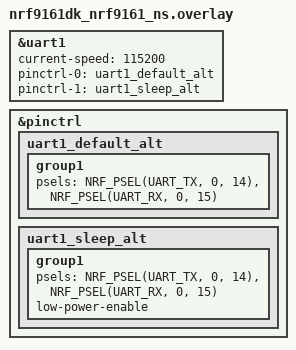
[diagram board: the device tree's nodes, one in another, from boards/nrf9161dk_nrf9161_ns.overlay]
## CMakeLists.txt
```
cmake_minimum_required(VERSION 3.20.0)

# Tell Zephyr where to find our custom YAML blueprints BEFORE finding Zephyr
list(APPEND DTS_ROOT ${CMAKE_CURRENT_SOURCE_DIR})

find_package(Zephyr REQUIRED HINTS $ENV{ZEPHYR_BASE})
project(EmbeddedSystem LANGUAGES C CXX)

zephyr_include_directories(include)

# Add both your main app AND your new kernel driver to the build
target_sources(app PRIVATE 
    src/main.cpp
    src/graphics.cpp
    src/shell.cpp
    src/state.cpp
    src/footprint.cpp
    src/virtual_sensor.c
)
```

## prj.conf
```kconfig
# Enable the hardware console peripheral and logging pipelines
CONFIG_GPIO=y
CONFIG_SERIAL=y
CONFIG_CONSOLE=y

# Enable internal GDB debugging hooks
CONFIG_DEBUG=y

# Disable heavy compiler optimization so code maps 1:1 with source files
CONFIG_DEBUG_OPTIMIZATIONS=y

# Enable the Display subsystem
CONFIG_DISPLAY=y

# Enable the SDL (Window) Display Driver
CONFIG_SDL_DISPLAY=y

# Enable standard C++ library support (provides the 'new' and 'delete' operators)
CONFIG_CPP=y

# Give the RTOS a standard system heap size
CONFIG_HEAP_MEM_POOL_SIZE=16384

# Set custom Boot Banner to 'Vidya OS'
CONFIG_BOOT_BANNER=y
CONFIG_BOOT_BANNER_STRING="Booting Vidya OS"

# Enable reboot APIs
CONFIG_REBOOT=y

# Enable full C++ standard library support (using host compiler's STL on native_sim)
CONFIG_REQUIRES_FULL_LIBCPP=y
CONFIG_STD_CPP17=y

# Enable standard Zephyr Sensor Subsystem
CONFIG_SENSOR=y

# Enable Zephyr's portable console subsystem and getline utilities
CONFIG_CONSOLE_SUBSYS=y
CONFIG_CONSOLE_GETLINE=y
```

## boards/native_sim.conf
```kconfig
# native_sim specific configurations
CONFIG_HEAP_MEM_POOL_SIZE=1048576
```

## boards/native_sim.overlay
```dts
/* boards/native_sim.overlay */

/ {
    my_custom_sensor: virtual_sensor_0 {
        compatible = "custom,virtual-sensor";
        status = "okay";
    };
};

&sdl_dc {
    status = "okay";
};
```

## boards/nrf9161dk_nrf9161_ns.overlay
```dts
&uart1 {
    status = "okay";
    current-speed = <115200>;
    pinctrl-0 = <&uart1_default_alt>;
    pinctrl-1 = <&uart1_sleep_alt>;
    pinctrl-names = "default", "sleep";
};

&pinctrl {
    uart1_default_alt: uart1_default_alt {
        group1 {
            psels = <NRF_PSEL(UART_TX, 0, 14)>,
                    <NRF_PSEL(UART_RX, 0, 15)>;
        };
    };

    uart1_sleep_alt: uart1_sleep_alt {
        group1 {
            psels = <NRF_PSEL(UART_TX, 0, 14)>,
                    <NRF_PSEL(UART_RX, 0, 15)>;
            low-power-enable;
        };
    };
};
```

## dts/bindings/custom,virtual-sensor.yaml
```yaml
# dts/bindings/custom,virtual-sensor.yaml
description: A custom virtual sensor for the OS simulator
compatible: "custom,virtual-sensor"
include: sensor-device.yaml
```

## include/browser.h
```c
#pragma once
// ─────────────────────────────────────────────────────────────────────────────
//  browser.h — Real internet browser backend for VidyaOS
//  Uses libcurl to fetch real HTTP/HTTPS pages and strips HTML to text.
// ─────────────────────────────────────────────────────────────────────────────
#include <string>
#include <vector>
#include <functional>

// ── Page link extracted from HTML ────────────────────────────────────────────
struct ParsedLink {
    std::string href;
    std::string text;
};

// ── Result of a fetch ────────────────────────────────────────────────────────
struct FetchResult {
    bool        success;
    int         http_code;       // 200, 404, etc.
    std::string final_url;       // After redirects
    std::string content_type;
    std::string raw_body;        // Full HTML
    std::string plain_text;      // Stripped text for display
    std::vector<std::string>     lines;  // pre-wrapped display lines
    std::vector<ParsedLink>      links;  // extracted <a href> links
    std::string error_message;
};

// ── Public API ───────────────────────────────────────────────────────────────

// Asynchronous fetch — triggers a background thread.
// Call is_fetching() to poll completion, then get_fetch_result().
void browser_fetch_async(const std::string& url);

// Returns true while a fetch is in progress.
bool browser_is_fetching();

// Returns the last completed fetch result. Safe to call from render thread.
const FetchResult& browser_get_result();

// Returns a normalised URL from user input (adds https:// etc.)
std::string browser_normalise_url(const std::string& input);

// Strip HTML tags and decode entities, return plain text lines.
std::vector<std::string> html_to_lines(const std::string& html, int wrap_chars, std::vector<ParsedLink>& links_out);
```

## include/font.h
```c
#ifndef FONT_H
#define FONT_H

#include <stdint.h>

static const uint8_t font8x8[96][8] = {
    {0x00, 0x00, 0x00, 0x00, 0x00, 0x00, 0x00, 0x00}, // (space)
    {0x18, 0x3C, 0x3C, 0x18, 0x18, 0x00, 0x18, 0x00}, // !
    {0x6C, 0x6C, 0x00, 0x00, 0x00, 0x00, 0x00, 0x00}, // "
    {0x36, 0x36, 0x7F, 0x36, 0x7F, 0x36, 0x36, 0x00}, // #
    {0x0C, 0x3E, 0x03, 0x1E, 0x30, 0x1F, 0x0C, 0x00}, // $
    {0x00, 0x66, 0x30, 0x18, 0x0C, 0x66, 0x00, 0x00}, // %
    {0x3C, 0x66, 0x3C, 0x38, 0x67, 0x66, 0x3F, 0x00}, // &
    {0x06, 0x0C, 0x18, 0x00, 0x00, 0x00, 0x00, 0x00}, // '
    {0x0C, 0x18, 0x30, 0x30, 0x30, 0x18, 0x0C, 0x00}, // (
    {0x30, 0x18, 0x0C, 0x0C, 0x0C, 0x18, 0x30, 0x00}, // )
    {0x00, 0x66, 0x3C, 0xFF, 0x3C, 0x66, 0x00, 0x00}, // *
    {0x00, 0x18, 0x18, 0x7E, 0x18, 0x18, 0x00, 0x00}, // +
    {0x00, 0x00, 0x00, 0x00, 0x00, 0x18, 0x18, 0x30}, // ,
    {0x00, 0x00, 0x00, 0x7E, 0x00, 0x00, 0x00, 0x00}, // -
    {0x00, 0x00, 0x00, 0x00, 0x00, 0x18, 0x18, 0x00}, // .
    {0x00, 0x03, 0x06, 0x0C, 0x18, 0x30, 0x60, 0x00}, // /
    {0x3E, 0x63, 0x67, 0x6F, 0x7B, 0x63, 0x3E, 0x00}, // 0
    {0x0C, 0x0E, 0x0C, 0x0C, 0x0C, 0x0C, 0x3F, 0x00}, // 1
    {0x1E, 0x33, 0x30, 0x1C, 0x06, 0x33, 0x3F, 0x00}, // 2
    {0x1E, 0x33, 0x30, 0x1C, 0x30, 0x33, 0x1E, 0x00}, // 3
    {0x38, 0x3C, 0x36, 0x33, 0x7F, 0x30, 0x78, 0x00}, // 4
    {0x3F, 0x03, 0x1F, 0x30, 0x30, 0x33, 0x1E, 0x00}, // 5
    {0x1C, 0x06, 0x03, 0x1F, 0x33, 0x33, 0x1E, 0x00}, // 6
    {0x3F, 0x33, 0x30, 0x18, 0x0C, 0x0C, 0x0C, 0x00}, // 7
    {0x1E, 0x33, 0x33, 0x1E, 0x33, 0x33, 0x1E, 0x00}, // 8
    {0x1E, 0x33, 0x33, 0x3E, 0x30, 0x18, 0x0E, 0x00}, // 9
    {0x00, 0x18, 0x18, 0x00, 0x18, 0x18, 0x00, 0x00}, // :
    {0x00, 0x18, 0x18, 0x00, 0x18, 0x18, 0x30, 0x00}, // ;
    {0x00, 0x0C, 0x18, 0x30, 0x18, 0x0C, 0x00, 0x00}, // <
    {0x00, 0x00, 0x7E, 0x00, 0x7E, 0x00, 0x00, 0x00}, // =
    {0x00, 0x30, 0x18, 0x0C, 0x18, 0x30, 0x00, 0x00}, // >
    {0x1E, 0x33, 0x30, 0x18, 0x0C, 0x00, 0x0C, 0x00}, // ?
    {0x3E, 0x63, 0x7B, 0x7B, 0x7B, 0x03, 0x1E, 0x00}, // @
    {0x0C, 0x1E, 0x33, 0x33, 0x3F, 0x33, 0x33, 0x00}, // A
    {0x3F, 0x66, 0x66, 0x3F, 0x66, 0x66, 0x3F, 0x00}, // B
    {0x3C, 0x66, 0x03, 0x03, 0x03, 0x66, 0x3C, 0x00}, // C
    {0x1F, 0x36, 0x66, 0x66, 0x66, 0x36, 0x1F, 0x00}, // D
    {0x3F, 0x06, 0x06, 0x1E, 0x06, 0x06, 0x3F, 0x00}, // E
    {0x3F, 0x06, 0x06, 0x1E, 0x06, 0x06, 0x06, 0x00}, // F
    {0x3C, 0x66, 0x03, 0x3B, 0x66, 0x66, 0x3C, 0x00}, // G
    {0x33, 0x33, 0x33, 0x3F, 0x33, 0x33, 0x33, 0x00}, // H
    {0x1E, 0x0C, 0x0C, 0x0C, 0x0C, 0x0C, 0x1E, 0x00}, // I
    {0x78, 0x30, 0x30, 0x30, 0x33, 0x33, 0x1E, 0x00}, // J
    {0x33, 0x36, 0x3C, 0x3C, 0x36, 0x33, 0x33, 0x00}, // K
    {0x06, 0x06, 0x06, 0x06, 0x06, 0x06, 0x3F, 0x00}, // L
    {0x63, 0x77, 0x7F, 0x6B, 0x63, 0x63, 0x63, 0x00}, // M
    {0x33, 0x3B, 0x3F, 0x37, 0x33, 0x33, 0x33, 0x00}, // N
    {0x1E, 0x33, 0x33, 0x33, 0x33, 0x33, 0x1E, 0x00}, // O
    {0x3F, 0x66, 0x66, 0x3F, 0x06, 0x06, 0x06, 0x00}, // P
    {0x1E, 0x33, 0x33, 0x33, 0x3B, 0x3B, 0x1E, 0x38}, // Q
    {0x3F, 0x66, 0x66, 0x3F, 0x36, 0x66, 0x63, 0x00}, // R
    {0x1E, 0x33, 0x07, 0x0E, 0x38, 0x33, 0x1E, 0x00}, // S
    {0x3F, 0x0C, 0x0C, 0x0C, 0x0C, 0x0C, 0x0C, 0x00}, // T
    {0x33, 0x33, 0x33, 0x33, 0x33, 0x33, 0x1E, 0x00}, // U
    {0x33, 0x33, 0x33, 0x33, 0x33, 0x1E, 0x0C, 0x00}, // V
    {0x63, 0x63, 0x63, 0x6B, 0x7F, 0x77, 0x63, 0x00}, // W
    {0x63, 0x63, 0x36, 0x1C, 0x36, 0x63, 0x63, 0x00}, // X
    {0x33, 0x33, 0x33, 0x1E, 0x0C, 0x0C, 0x0C, 0x00}, // Y
    {0x3F, 0x30, 0x18, 0x0C, 0x06, 0x03, 0x3F, 0x00}, // Z
    {0x3C, 0x0C, 0x0C, 0x0C, 0x0C, 0x0C, 0x3C, 0x00}, // [
    {0x00, 0x60, 0x30, 0x18, 0x0C, 0x06, 0x03, 0x00}, // backslash
    {0x3C, 0x30, 0x30, 0x30, 0x30, 0x30, 0x3C, 0x00}, // ]
    {0x08, 0x1C, 0x36, 0x63, 0x00, 0x00, 0x00, 0x00}, // ^
    {0x00, 0x00, 0x00, 0x00, 0x00, 0x00, 0x00, 0xFF}, // _
    {0x0C, 0x06, 0x03, 0x00, 0x00, 0x00, 0x00, 0x00}, // `
    {0x00, 0x00, 0x3E, 0x30, 0x3E, 0x33, 0x3E, 0x00}, // a
    {0x06, 0x06, 0x3E, 0x33, 0x33, 0x33, 0x3E, 0x00}, // b
    {0x00, 0x00, 0x3E, 0x03, 0x03, 0x03, 0x3E, 0x00}, // c
    {0x30, 0x30, 0x3E, 0x33, 0x33, 0x33, 0x3E, 0x00}, // d
    {0x00, 0x00, 0x3E, 0x33, 0x3F, 0x03, 0x3E, 0x00}, // e
    {0x1C, 0x36, 0x06, 0x1F, 0x06, 0x06, 0x06, 0x00}, // f
    {0x00, 0x00, 0x3E, 0x33, 0x33, 0x3E, 0x30, 0x1F}, // g
    {0x06, 0x06, 0x3E, 0x33, 0x33, 0x33, 0x33, 0x00}, // h
    {0x0C, 0x00, 0x0E, 0x0C, 0x0C, 0x0C, 0x1E, 0x00}, // i
    {0x30, 0x00, 0x30, 0x30, 0x30, 0x33, 0x33, 0x1E}, // j
    {0x06, 0x06, 0x33, 0x36, 0x3C, 0x36, 0x33, 0x00}, // k
    {0x0E, 0x0C, 0x0C, 0x0C, 0x0C, 0x0C, 0x1E, 0x00}, // l
    {0x00, 0x00, 0x66, 0x7F, 0x6B, 0x63, 0x63, 0x00}, // m
    {0x00, 0x00, 0x3E, 0x33, 0x33, 0x33, 0x33, 0x00}, // n
    {0x00, 0x00, 0x1E, 0x33, 0x33, 0x33, 0x1E, 0x00}, // o
    {0x00, 0x00, 0x3E, 0x33, 0x33, 0x3E, 0x06, 0x06}, // p
    {0x00, 0x00, 0x3E, 0x33, 0x33, 0x3E, 0x30, 0x30}, // q
    {0x00, 0x00, 0x3E, 0x33, 0x07, 0x06, 0x06, 0x00}, // r
    {0x00, 0x00, 0x1E, 0x03, 0x1E, 0x30, 0x1F, 0x00}, // s
    {0x08, 0x08, 0x3E, 0x08, 0x08, 0x08, 0x1C, 0x00}, // t
    {0x00, 0x00, 0x33, 0x33, 0x33, 0x33, 0x3E, 0x00}, // u
    {0x00, 0x00, 0x33, 0x33, 0x33, 0x1E, 0x0C, 0x00}, // v
    {0x00, 0x00, 0x63, 0x6B, 0x7F, 0x36, 0x22, 0x00}, // w
    {0x00, 0x00, 0x63, 0x36, 0x1C, 0x36, 0x63, 0x00}, // x
    {0x00, 0x00, 0x33, 0x33, 0x33, 0x3E, 0x30, 0x1F}, // y
    {0x00, 0x00, 0x3F, 0x30, 0x18, 0x0C, 0x3F, 0x00}, // z
    {0x18, 0x0C, 0x0C, 0x06, 0x0C, 0x0C, 0x18, 0x00}, // {
    {0x18, 0x18, 0x18, 0x00, 0x18, 0x18, 0x18, 0x00}, // |
    {0x30, 0x18, 0x18, 0x0C, 0x18, 0x18, 0x30, 0x00}, // }
    {0x00, 0x00, 0x00, 0x76, 0x3B, 0x00, 0x00, 0x00}, // ~
    {0x00, 0x00, 0x00, 0x00, 0x00, 0x00, 0x00, 0x00}  // rubout
};

#endif // FONT_H
```

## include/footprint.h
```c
#ifndef FOOTPRINT_H
#define FOOTPRINT_H

#include <string>
#include <unordered_map>
#include <vector>
#include <cstdint>

// Lightweight, self-contained SHA-256 implementation
class SHA256 {
private:
    uint32_t state[8];
    uint64_t bitlen;
    uint8_t data[64];
    uint32_t datalen;

    void transform(const uint8_t *data);
    static inline uint32_t CH(uint32_t x, uint32_t y, uint32_t z) { return (x & y) ^ (~x & z); }
    static inline uint32_t MAJ(uint32_t x, uint32_t y, uint32_t z) { return (x & y) ^ (x & z) ^ (y & z); }
    static inline uint32_t EP0(uint32_t x) { return ROTR(x, 2) ^ ROTR(x, 13) ^ ROTR(x, 22); }
    static inline uint32_t EP1(uint32_t x) { return ROTR(x, 6) ^ ROTR(x, 11) ^ ROTR(x, 25); }
    static inline uint32_t SIG0(uint32_t x) { return ROTR(x, 7) ^ ROTR(x, 18) ^ (x >> 3); }
    static inline uint32_t SIG1(uint32_t x) { return ROTR(x, 17) ^ ROTR(x, 19) ^ (x >> 10); }
    static inline uint32_t ROTR(uint32_t x, uint32_t n) { return (x >> n) | (x << (32 - n)); }

    static const uint32_t k[64];

public:
    SHA256();
    void update(const uint8_t *data, size_t len);
    void update(const std::string& str);
    std::string finalize();
};

// Utility function to compute SHA-256 of a string
std::string sha256(const std::string& input);

class FootprintTracker {
private:
    std::unordered_map<std::string, std::string> stored_footprint;
    std::unordered_map<std::string, std::string> active_footprint;

    // Helper to propagate hash modifications up to the root
    void propagate_hash(std::unordered_map<std::string, std::string>& footprint, const std::string& path);

public:
    FootprintTracker();

    // Rebuild active footprint entirely from virtual_files, and sync to stored_footprint
    void snapshot();

    // Rebuild active footprint on-demand from current virtual_files
    void rebuild_active_footprint();

    // Diff stored_footprint and active_footprint
    void diff(std::vector<std::string>& added, 
              std::vector<std::string>& removed, 
              std::vector<std::string>& modified);

    // Updates a path in stored_footprint from the active footprint, propagating changes up
    void update(const std::string& path);

    // Triggered upon file system changes. Recalculates active footprint incrementally.
    void notify_change(const std::string& path);

    // Returns the root hash of the directory "/" (active or stored)
    std::string get_root_hash(bool active = true) const;

    // Checks if a path is a directory in active/stored footprint
    bool is_stored_dir(const std::string& path) const;
    bool is_active_dir(const std::string& path) const;

    // Save and load stored footprint from virtual file and host disk backing store
    bool save_to_disk(const std::string& virtual_path);
    bool load_from_disk(const std::string& virtual_path);

    bool isPathChanged(const std::string& path) const;
};

// Global instance of the tracker
extern FootprintTracker mft;

#endif // FOOTPRINT_H
```

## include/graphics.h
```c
#ifndef GRAPHICS_H
#define GRAPHICS_H

#include <SDL2/SDL.h>
#include <SDL2/SDL_ttf.h>
#include <stdint.h>

// Initialise TrueType font system — call once after SDL_Init succeeds
bool init_fonts(SDL_Renderer *renderer);
void close_fonts();

// Main render entry point — draws the complete desktop frame directly to the renderer
void draw_desktop(SDL_Renderer *renderer, int screen_w, int screen_h);

// Accent color helper (also used by state.cpp)
uint32_t get_accent_color();

#endif // GRAPHICS_H
```

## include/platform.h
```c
#ifndef PLATFORM_H
#define PLATFORM_H

#ifdef __ZEPHYR__
#include <zephyr/kernel.h>
#include <zephyr/drivers/display.h>
#include <zephyr/sys/reboot.h>
#include <zephyr/device.h>
#include <zephyr/drivers/sensor.h>
#include <zephyr/console/console.h>
#else
#include <iostream>
#include <thread>
#include <chrono>
#include <stdlib.h>

struct device {
    const char *name;
};

struct sensor_value {
    int val1;
    int val2;
};

#define SENSOR_CHAN_AMBIENT_TEMP 0

inline void console_getline_init() {}
inline char* console_getline() {
    static std::string input_buf;
    if (std::getline(std::cin, input_buf)) {
        return &input_buf[0];
    }
    // Exit simulator gracefully on stdin EOF (e.g. piped input completes)
    exit(0);
}

#define printk printf
#define k_msleep(ms) std::this_thread::sleep_for(std::chrono::milliseconds(ms))
#define sys_reboot(type) do { printf("\n[MOCK] System Rebooting...\n"); exit(0); } while(0)
#define SYS_REBOOT_COLD 0
#define device_is_ready(dev) (false)

static struct device mock_devices[] = {
    {"CPU_0"},
    {"UART_CONSOLE"},
    {"VIRTUAL_DISPLAY"},
    {"KEYBOARD"},
    {"TEMPERATURE_SENSOR"}
};

inline size_t z_device_get_all_static(const struct device **devices) {
    *devices = mock_devices;
    return sizeof(mock_devices) / sizeof(struct device);
}

inline int sensor_sample_fetch(const struct device *dev) { return 0; }
inline int sensor_channel_get(const struct device *dev, int chan, struct sensor_value *val) {
    static int mock_temp = 20;
    mock_temp += 2;
    if (mock_temp > 50) mock_temp = 20;
    val->val1 = mock_temp;
    val->val2 = 0;
    return 0;
}
#endif

// ANSI Escape Codes for CLI Colors
#define ANSI_RESET   "\033[0m"
#define ANSI_BOLD    "\033[1m"
#define ANSI_RED     "\033[31m"
#define ANSI_GREEN   "\033[32m"
#define ANSI_YELLOW  "\033[33m"
#define ANSI_BLUE    "\033[34m"
#define ANSI_MAGENTA "\033[35m"
#define ANSI_CYAN    "\033[36m"
#define ANSI_WHITE   "\033[37m"

extern const struct device *sensor_dev;

#endif // PLATFORM_H
```

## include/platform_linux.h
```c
#ifndef PLATFORM_LINUX_H
#define PLATFORM_LINUX_H

#include <string>
#include <vector>

// --- User Database Operations ---
bool authenticate_user(const std::string& username, const std::string& password);
bool add_user_native(const std::string& username, const std::string& password);
bool delete_user_native(const std::string& username);
std::vector<std::string> get_users_list_native();

// --- Network Operations ---
void update_network_telemetry_native();
std::vector<std::string> scan_networks_native();
bool connect_network_native(const std::string& ssid);
void disconnect_network_native();

// --- Filesystem Operations ---
bool check_permission_native(const std::string& path, bool write_req);
void sync_sandbox_to_virtual_files_native();

#endif // PLATFORM_LINUX_H
```

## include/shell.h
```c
#ifndef SHELL_H
#define SHELL_H

#include <string>

void print_help();
void execute_os_command(const std::string& line_str);
void shell_thread_entry(void *p1, void *p2, void *p3);
void set_default_metadata(const std::string& path, bool is_dir);

#endif // SHELL_H
```

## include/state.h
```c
#ifndef STATE_H
#define STATE_H

#include <string>
#include <vector>
#include <map>
#include <cstdint>

struct Window {
    const char *title;
    int x, y, w, h;
    bool open;
    int zOrder;
    bool minimized;
    bool hasTitleBar;
    int workspace; // 0..3
};

struct SDL_Window;

struct Notification {
    std::string message;
    int timestamp; // mock unix or tick time
};

extern bool sensor_logging_enabled;
extern bool system_locked;
extern std::string lock_password;
extern std::map<std::string, std::string> virtual_files;
extern std::string current_working_directory;
extern Window windows[8];
extern bool start_menu_open;
extern bool is_dark_theme;
extern std::string selected_file;
extern int mouse_x;
extern int mouse_y;
extern std::vector<std::string> terminal_logs;
extern std::vector<int> sensor_history;
extern int current_sensor_value;
extern std::string gui_input_buffer;

// --- Phase 2 Dragging & Window Manager ---
extern int dragging_window_index;
extern int drag_offset_x;
extern int drag_offset_y;

// --- Phase 2 Settings Customizer ---
extern int settings_active_tab;
extern int settings_wallpaper_idx;
extern int settings_accent_idx;
extern int settings_font_size;
extern bool wifi_enabled;
extern std::string wifi_ssid;
extern bool vpn_enabled;
extern int system_volume;
extern bool system_muted;
extern int sound_device_idx;
extern bool notifications_enabled;
extern std::vector<std::string> virtual_users;
extern int update_check_progress;
extern std::string last_update_check_time;

// --- Phase 2 Notification Centre ---
extern std::vector<Notification> notifications;
extern bool notifications_popup_open;
void push_notification(const std::string& msg);

// --- Phase 2 Clipboard ---
extern std::string global_clipboard_path;

// --- Phase 2 Text Editor ---
extern std::string editor_text_content;
extern std::string editor_current_file;
extern int editor_cursor_pos;
extern std::string editor_undo_buffer;

// --- Phase 2 System Monitor Scrolling Graphs ---
extern std::vector<int> cpu_history;
extern std::vector<int> ram_history;

// --- Phase 2 File Manager 2.0 tree & context menu ---
extern std::string file_manager_current_dir;
extern std::vector<std::string> file_manager_expanded_dirs;
extern bool file_manager_context_menu_open;
extern int file_manager_context_menu_x;
extern int file_manager_context_menu_y;
extern std::string file_manager_context_menu_target;
extern std::vector<std::string> footprint_added;
extern std::vector<std::string> footprint_removed;
extern std::vector<std::string> footprint_modified;
extern bool footprint_has_diff;


extern std::map<std::string, bool> apt_installed_packages;
extern std::string chrome_url;
extern bool chrome_address_active;
extern bool cmatrix_active;
extern int gui_frame_counter;

extern bool python_repl_active;
extern std::map<std::string, std::string> python_variables;
extern std::map<std::string, bool> java_compiled_classes;
extern std::map<std::string, std::string> compiled_binaries;

extern bool javascript_repl_active;
extern std::map<std::string, std::string> javascript_variables;

void handle_desktop_click(int x, int y, bool is_double_click = false);
void handle_right_click(int x, int y);
void save_settings_to_file();
void load_settings_from_file();
void add_terminal_log(const std::string& line);
bool is_focused_window(int idx);

extern int telemetry_cpu_usage;
extern int telemetry_ram_usage;
extern std::string telemetry_json_output;

// --- Phase 1 Additions ---
extern int window_z_order[8];
void bring_to_front(int index);

extern std::string file_manager_viewing_content;
extern std::string file_manager_viewing_title;

extern SDL_Window* sdl_window;
extern int current_window_scale;

// ── Modern UI Layout Constants (native resolution) ──────────────────────
// These are defined as constants here and computed dynamically in graphics.cpp
// based on the actual display width/height.
#define TASKBAR_H   48      // height of the bottom dock/taskbar
#define TITLEBAR_H  32      // height of each window's title bar
#define ICON_SZ     64      // desktop icon square size
#define CORNER_R    8       // window corner rounding radius (approx)

#define ICO_START_X 24
#define ICO_START_Y 24
#define ICO_STEP_X  96
#define ICO_STEP_Y  96

// Terminal dimensions — larger at native resolution (fits a ~600×400 window)
#define TERM_COLS   70
#define TERM_ROWS   22

struct VTerm;
struct VTermScreen;
extern VTerm* vterm_instance;
extern VTermScreen* vterm_screen;
extern bool bash_shell_active;
extern int pty_master_fd;
extern int shell_pid;

std::string get_sandbox_root();
std::string translate_path(const std::string& internal_path);
std::string resolve_path(const std::string& path);
void sync_sandbox_to_virtual_files();

// --- Phase 3 Networking ---
struct NetworkState {
    bool wifiOn;
    std::string ssid;
    int signalStrength;
    bool vpn;
    std::string ipAddress;
};
extern NetworkState net_state;
extern std::vector<std::string> available_networks;

// --- Phase 3 Multi-User & Security ---
extern std::string currentUser;
struct FileMeta {
    std::string owner;
    int permissions; // e.g. 0755
};
extern std::map<std::string, FileMeta> file_metadata;
extern bool system_logged_in;
extern std::string login_input_buffer;
extern std::string login_pass_buffer;
extern int login_selected_user_idx;
extern std::map<std::string, std::string> user_passwords; // username -> sha256_hash
extern bool firewall_allow_incoming;
extern std::map<std::string, bool> firewall_rules; // app -> allowed

// --- Phase 3 Workspaces ---
extern int current_workspace;
extern int settings_wallpapers[4]; // Wallpapers for workspace 0..3

// --- Phase 3 Themes Engine ---
struct Theme {
    std::string name;
    uint32_t window_bg[8]; // individual bg color for each of the 8 windows
    uint32_t titlebar_bg;
    uint32_t titlebar_fg;
    uint32_t taskbar_bg;
    uint32_t font_color;
    uint32_t accent;
    int font_size;
    int wallpaper;
};
extern Theme active_theme;
extern std::vector<Theme> installed_themes;

// --- Phase 3 App Store ---
extern int appstore_active_category; // 0: All, 1: Dev, 2: Utils, 3: Games, 4: Themes
extern int appstore_installing_idx;  // index of app currently installing (-1 if none)
extern int appstore_progress;        // 0..100
struct AppStoreItem {
    std::string name;
    std::string package_name;
    std::string desc;
    int rating;
    std::string size;
    uint32_t color; // representation color for mock screenshot
    std::string category;
};
extern std::vector<AppStoreItem> appstore_apps;

// --- Phase 3 Browser Upgrade ---
extern std::vector<std::string> browser_history;
extern int browser_history_idx;
struct WebLink {
    int x1, y1, x2, y2;
    std::string url;
};
extern std::vector<WebLink> browser_links;

void set_default_metadata(const std::string& path, bool is_dir);
uint32_t get_accent_color();

// --- Phase 5 OS features ---
extern bool is_tiling_mode;

struct DownloadItem {
    std::string filename;
    int progress; // 0..100
    bool completed;
};
extern std::vector<DownloadItem> browser_downloads;
extern std::vector<std::string> browser_bookmarks;

struct TermPane {
    std::string title;
    std::vector<std::string> logs;
    std::string input_buffer;
    bool active;
};
extern std::vector<TermPane> term_panes;
extern int active_term_pane_idx;
extern bool dev_mode_enabled;
extern std::string active_system_slot;
extern std::string inactive_system_slot;
extern bool slot_upgrade_pending;

extern bool apparmor_enabled;
extern std::vector<std::string> firewall_blocked_apps;

struct IoTDevice {
    std::string name;
    std::string type;
    std::string state;
};
extern std::vector<IoTDevice> iot_devices;

extern bool voice_assistant_active;
extern std::string voice_assistant_input;

extern bool screen_reader_enabled;
extern std::string current_locale;

extern bool bluetooth_enabled;
extern std::vector<std::string> bluetooth_devices;

extern bool editor_terminal_focused;
extern bool downloads_panel_open;

void get_tiled_bounds(int open_count, int index_in_tiled, int screen_w, int screen_h, int& ox, int& oy, int& ow, int& oh);

#endif // STATE_H
```

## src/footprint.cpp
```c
#include "footprint.h"
#include "state.h"
#include <algorithm>
#include <filesystem>
#include <fstream>
#include <sstream>
#include <iomanip>
#include <set>
#include <cstdint>
#include <cstring>

// Global instance of the FootprintTracker
FootprintTracker mft;

// -------------------------------------------------------------
//  SHA-256 implementation
// -------------------------------------------------------------
const uint32_t SHA256::k[64] = {
    0x428a2f98,0x71374491,0xb5c0fbcf,0xe9b5dba5,0x3956c25b,0x59f111f1,0x923f82a4,0xab1c5ed5,
    0xd807aa98,0x12835b01,0x243185be,0x550c7dc3,0x72be5d74,0x80deb1fe,0x9bdc06a7,0xc19bf174,
    0xe49b69c1,0xefbe4786,0x0fc19dc6,0x240ca1cc,0x2de92c6f,0x4a7484aa,0x5cb0a9dc,0x76f988da,
    0x983e5152,0xa831c66d,0xb00327c8,0xbf597fc7,0xc6e00bf3,0xd5a79147,0x06ca6351,0x14292967,
    0x27b70a85,0x2e1b2138,0x4d2c6dfc,0x53380d13,0x650a7354,0x766a0abb,0x81c2c92e,0x92722c85,
    0xa2bfe8a1,0xa81a664b,0xc24b8b70,0xc76c51a3,0xd192e819,0xd6990624,0xf40e3585,0x106aa070,
    0x19a4c116,0x1e376c08,0x2748774c,0x34b0bcb5,0x391c0cb3,0x4ed8aa4a,0x5b9cca4f,0x682e6ff3,
    0x748f82ee,0x78a5636f,0x84c87814,0x8cc70208,0x90befffa,0xa4506ceb,0xbef9a3f7,0xc67178f2
};

SHA256::SHA256() {
    state[0] = 0x6a09e667;
    state[1] = 0xbb67ae85;
    state[2] = 0x3c6ef372;
    state[3] = 0xa54ff53a;
    state[4] = 0x510e527f;
    state[5] = 0x9b05688c;
    state[6] = 0x1f83d9ab;
    state[7] = 0x5be0cd19;
    bitlen = 0;
    datalen = 0;
}

void SHA256::transform(const uint8_t *data) {
    uint32_t a, b, c, d, e, f, g, h, i, j, t1, t2, m[64];

    for (i = 0, j = 0; i < 16; ++i, j += 4)
        m[i] = (data[j] << 24) | (data[j + 1] << 16) | (data[j + 2] << 8) | (data[j + 3]);
    for ( ; i < 64; ++i)
        m[i] = SIG1(m[i - 2]) + m[i - 7] + SIG0(m[i - 15]) + m[i - 16];

    a = state[0];
    b = state[1];
    c = state[2];
    d = state[3];
    e = state[4];
    f = state[5];
    g = state[6];
    h = state[7];

    for (i = 0; i < 64; ++i) {
        t1 = h + EP1(e) + CH(e, f, g) + k[i] + m[i];
        t2 = EP0(a) + MAJ(a, b, c);
        h = g;
        g = f;
        f = e;
        e = d + t1;
        d = c;
        c = b;
        b = a;
        a = t1 + t2;
    }

    state[0] += a;
    state[1] += b;
    state[2] += c;
    state[3] += d;
    state[4] += e;
    state[5] += f;
    state[6] += g;
    state[7] += h;
}

void SHA256::update(const uint8_t *data, size_t len) {
    for (size_t i = 0; i < len; ++i) {
        this->data[datalen] = data[i];
        datalen++;
        if (datalen == 64) {
            transform(this->data);
            bitlen += 512;
            datalen = 0;
        }
    }
}

void SHA256::update(const std::string& str) {
    update(reinterpret_cast<const uint8_t*>(str.data()), str.size());
}

std::string SHA256::finalize() {
    uint8_t i = datalen;

    if (datalen < 56) {
        data[i++] = 0x80;
        while (i < 56)
            data[i++] = 0x00;
    } else {
        data[i++] = 0x80;
        while (i < 64)
            data[i++] = 0x00;
        transform(data);
        memset(data, 0, 56);
    }

    bitlen += datalen * 8;
    data[63] = bitlen;
    data[62] = bitlen >> 8;
    data[61] = bitlen >> 16;
    data[60] = bitlen >> 24;
    data[59] = bitlen >> 32;
    data[58] = bitlen >> 40;
    data[57] = bitlen >> 48;
    data[56] = bitlen >> 56;
    transform(data);

    std::stringstream ss;
    for (int i = 0; i < 8; ++i) {
        ss << std::hex << std::setw(8) << std::setfill('0') << state[i];
    }
    return ss.str();
}

std::string sha256(const std::string& input) {
    SHA256 sha;
    sha.update(input);
    return sha.finalize();
}

// -------------------------------------------------------------
//  Helper utilities for path traversal
// -------------------------------------------------------------
static std::string getParent(const std::string& path) {
    if (path == "/") return "";
    size_t last_slash = path.find_last_of('/');
    if (last_slash == std::string::npos) return "";
    if (last_slash == 0) return "/";
    return path.substr(0, last_slash);
}

static std::vector<std::string> get_immediate_children(const std::unordered_map<std::string, std::string>& footprint, const std::string& parent) {
    std::vector<std::string> children;
    for (const auto& [k, v] : footprint) {
        if (k != parent && getParent(k) == parent) {
            children.push_back(k);
        }
    }
    return children;
}

// -------------------------------------------------------------
//  FootprintTracker implementation
// -------------------------------------------------------------
FootprintTracker::FootprintTracker() {}

void FootprintTracker::propagate_hash(std::unordered_map<std::string, std::string>& footprint, const std::string& path) {
    std::string curr = getParent(path);
    while (!curr.empty()) {
        std::vector<std::string> children = get_immediate_children(footprint, curr);
        std::sort(children.begin(), children.end());

        std::string concat_hashes = "";
        for (const auto& child : children) {
            concat_hashes += footprint[child];
        }
        footprint[curr] = sha256(concat_hashes);

        if (curr == "/") break;
        curr = getParent(curr);
    }
}

void FootprintTracker::snapshot() {
    sync_sandbox_to_virtual_files();
    active_footprint.clear();

    // 1. Discover all files and directories
    std::set<std::string> directories;
    directories.insert("/");

    for (const auto& [path, content] : virtual_files) {
        if (content == "<dir>") {
            directories.insert(path);
        } else {
            // It's a file. Set its active hash directly from content.
            active_footprint[path] = sha256(content);
            // Trace and insert parent directories
            std::string parent = getParent(path);
            while (!parent.empty()) {
                directories.insert(parent);
                if (parent == "/") break;
                parent = getParent(parent);
            }
        }
    }

    // Include directory entries in active footprint
    for (const auto& dir : directories) {
        if (active_footprint.count(dir) == 0) {
            active_footprint[dir] = ""; // temporary hash, will compute bottom-up
        }
    }

    // 2. Sort all paths by length in descending order for bottom-up computation
    std::vector<std::string> sorted_paths;
    for (const auto& [path, _] : active_footprint) {
        sorted_paths.push_back(path);
    }
    std::sort(sorted_paths.begin(), sorted_paths.end(), [](const std::string& a, const std::string& b) {
        return a.length() > b.length();
    });

    // 3. Pre-build children map for fast O(N) lookup
    std::unordered_map<std::string, std::vector<std::string>> parent_to_children;
    for (const auto& path : sorted_paths) {
        std::string parent = getParent(path);
        if (!parent.empty()) {
            parent_to_children[parent].push_back(path);
        }
    }

    // 4. Compute hashes bottom-up
    for (const auto& path : sorted_paths) {
        // If it's a directory (i.e. present in our directories set)
        if (directories.count(path)) {
            std::vector<std::string> children = parent_to_children[path];
            std::sort(children.begin(), children.end());
            
            std::string concat = "";
            for (const auto& child : children) {
                concat += active_footprint[child];
            }
            active_footprint[path] = sha256(concat);
        }
    }

    // 5. Store snapshot in memory
    stored_footprint = active_footprint;

    // 6. Save to virtual filesystem /var/footprint.db and host footprint.db
    save_to_disk("/var/footprint.db");
}

void FootprintTracker::rebuild_active_footprint() {
    active_footprint.clear();

    // 1. Discover all files and directories
    std::set<std::string> directories;
    directories.insert("/");

    for (const auto& [path, content] : virtual_files) {
        if (content == "<dir>") {
            directories.insert(path);
        } else {
            // It's a file. Set its active hash directly from content.
            active_footprint[path] = sha256(content);
            // Trace and insert parent directories
            std::string parent = getParent(path);
            while (!parent.empty()) {
                directories.insert(parent);
                if (parent == "/") break;
                parent = getParent(parent);
            }
        }
    }

    // Include directory entries in active footprint
    for (const auto& dir : directories) {
        if (active_footprint.count(dir) == 0) {
            active_footprint[dir] = ""; // temporary hash, will compute bottom-up
        }
    }

    // 2. Sort all paths by length in descending order for bottom-up computation
    std::vector<std::string> sorted_paths;
    for (const auto& [path, _] : active_footprint) {
        sorted_paths.push_back(path);
    }
    std::sort(sorted_paths.begin(), sorted_paths.end(), [](const std::string& a, const std::string& b) {
        return a.length() > b.length();
    });

    // 3. Pre-build children map for fast O(N) lookup
    std::unordered_map<std::string, std::vector<std::string>> parent_to_children;
    for (const auto& path : sorted_paths) {
        std::string parent = getParent(path);
        if (!parent.empty()) {
            parent_to_children[parent].push_back(path);
        }
    }

    // 4. Compute hashes bottom-up
    for (const auto& path : sorted_paths) {
        // If it's a directory (i.e. present in our directories set)
        if (directories.count(path)) {
            std::vector<std::string> children = parent_to_children[path];
            std::sort(children.begin(), children.end());
            
            std::string concat = "";
            for (const auto& child : children) {
                concat += active_footprint[child];
            }
            active_footprint[path] = sha256(concat);
        }
    }
}

void FootprintTracker::diff(std::vector<std::string>& added, 
                            std::vector<std::string>& removed, 
                            std::vector<std::string>& modified) {
    added.clear();
    removed.clear();
    modified.clear();

    // Loop through current active footprint to find added and modified files
    for (const auto& [path, active_hash] : active_footprint) {
        auto it = stored_footprint.find(path);
        if (it == stored_footprint.end()) {
            added.push_back(path);
        } else if (it->second != active_hash) {
            modified.push_back(path);
        }
    }

    // Loop through stored footprint to find removed files
    for (const auto& [path, stored_hash] : stored_footprint) {
        if (active_footprint.count(path) == 0) {
            removed.push_back(path);
        }
    }

    std::sort(added.begin(), added.end());
    std::sort(removed.begin(), removed.end());
    std::sort(modified.begin(), modified.end());

    footprint_added = added;
    footprint_removed = removed;
    footprint_modified = modified;
    footprint_has_diff = true;
}

void FootprintTracker::update(const std::string& path) {
    if (path.empty()) {
        // Sync whole stored_footprint to active_footprint
        stored_footprint = active_footprint;
        save_to_disk("/var/footprint.db");
        return;
    }

    // Check if the path exists in the active footprint
    auto it = active_footprint.find(path);
    if (it != active_footprint.end()) {
        stored_footprint[path] = it->second;
    } else {
        // Erase path and all descendants from stored footprint
        std::string prefix = path + "/";
        for (auto sit = stored_footprint.begin(); sit != stored_footprint.end(); ) {
            if (sit->first == path || sit->first.rfind(prefix, 0) == 0) {
                sit = stored_footprint.erase(sit);
            } else {
                ++sit;
            }
        }
    }

    // Propagate change up the directory tree in stored footprint
    propagate_hash(stored_footprint, path);
    save_to_disk("/var/footprint.db");
}

void FootprintTracker::notify_change(const std::string& path) {
    // Check if file still exists in virtual_files
    auto it = virtual_files.find(path);
    if (it != virtual_files.end()) {
        if (it->second == "<dir>") {
            // Keep empty hash temporarily, will be updated via children propagation if any exist.
            active_footprint[path] = sha256("");
        } else {
            active_footprint[path] = sha256(it->second);
        }
    } else {
        // Path was deleted. Erase it and all descendants from active footprint.
        std::string prefix = path + "/";
        for (auto ait = active_footprint.begin(); ait != active_footprint.end(); ) {
            if (ait->first == path || ait->first.rfind(prefix, 0) == 0) {
                ait = active_footprint.erase(ait);
            } else {
                ++ait;
            }
        }
    }

    // Propagate hash changes up to the root in active footprint
    propagate_hash(active_footprint, path);
}

std::string FootprintTracker::get_root_hash(bool active) const {
    const auto& m = active ? active_footprint : stored_footprint;
    auto it = m.find("/");
    if (it != m.end()) {
        return it->second;
    }
    return "";
}

// -------------------------------------------------------------
//  Serialization & Deserialization
// -------------------------------------------------------------
static std::string serialize_map_to_json(const std::unordered_map<std::string, std::string>& m) {
    std::string out = "{\n";
    size_t i = 0;
    for (const auto& [k, v] : m) {
        out += "  \"" + k + "\": \"" + v + "\"";
        if (++i < m.size()) out += ",";
        out += "\n";
    }
    out += "}";
    return out;
}

static std::unordered_map<std::string, std::string> deserialize_json_to_map(const std::string& json) {
    std::unordered_map<std::string, std::string> m;
    size_t pos = 0;
    while (true) {
        size_t key_start = json.find('"', pos);
        if (key_start == std::string::npos) break;
        size_t key_end = json.find('"', key_start + 1);
        if (key_end == std::string::npos) break;
        std::string key = json.substr(key_start + 1, key_end - key_start - 1);
        
        size_t colon = json.find(':', key_end + 1);
        if (colon == std::string::npos) break;
        
        size_t val_start = json.find('"', colon + 1);
        if (val_start == std::string::npos) break;
        size_t val_end = json.find('"', val_start + 1);
        if (val_end == std::string::npos) break;
        std::string val = json.substr(val_start + 1, val_end - val_start - 1);
        
        m[key] = val;
        pos = val_end + 1;
    }
    return m;
}

bool FootprintTracker::save_to_disk(const std::string& virtual_path) {
    std::string json_str = serialize_map_to_json(stored_footprint);
    virtual_files[virtual_path] = json_str;

    // Translate virtual path to sandboxed physical path
    std::string real_path = translate_path(virtual_path);
    try {
        std::filesystem::create_directories(std::filesystem::path(real_path).parent_path());
    } catch (...) {}

    std::ofstream f1(real_path);
    if (f1.is_open()) {
        f1 << json_str;
        f1.close();
        return true;
    }
    return false;
}

bool FootprintTracker::load_from_disk(const std::string& virtual_path) {
    std::string json_str = "";

    // Translate virtual path to sandboxed physical path
    std::string real_path = translate_path(virtual_path);
    std::ifstream f1(real_path);
    if (f1.is_open()) {
        json_str.assign((std::istreambuf_iterator<char>(f1)), std::istreambuf_iterator<char>());
        f1.close();
    }

    // If still empty, check if it exists in virtual_files
    if (json_str.empty()) {
        auto it = virtual_files.find(virtual_path);
        if (it != virtual_files.end()) {
            json_str = it->second;
        }
    }

    if (!json_str.empty()) {
        stored_footprint = deserialize_json_to_map(json_str);
        virtual_files[virtual_path] = json_str;
        
        // Build active footprint from current live virtual_files
        active_footprint.clear();
        std::set<std::string> directories;
        directories.insert("/");

        for (const auto& [path, content] : virtual_files) {
            if (content == "<dir>") {
                directories.insert(path);
            } else {
                active_footprint[path] = sha256(content);
                std::string parent = getParent(path);
                while (!parent.empty()) {
                    directories.insert(parent);
                    if (parent == "/") break;
                    parent = getParent(parent);
                }
            }
        }
        for (const auto& dir : directories) {
            if (active_footprint.count(dir) == 0) {
                active_footprint[dir] = "";
            }
        }

        std::vector<std::string> sorted_paths;
        for (const auto& [path, _] : active_footprint) {
            sorted_paths.push_back(path);
        }
        std::sort(sorted_paths.begin(), sorted_paths.end(), [](const std::string& a, const std::string& b) {
            return a.length() > b.length();
        });

        std::unordered_map<std::string, std::vector<std::string>> parent_to_children;
        for (const auto& path : sorted_paths) {
            std::string parent = getParent(path);
            if (!parent.empty()) {
                parent_to_children[parent].push_back(path);
            }
        }

        for (const auto& path : sorted_paths) {
            if (directories.count(path)) {
                std::vector<std::string> children = parent_to_children[path];
                std::sort(children.begin(), children.end());
                std::string concat = "";
                for (const auto& child : children) {
                    concat += active_footprint[child];
                }
                active_footprint[path] = sha256(concat);
            }
        }
        return true;
    }
    return false;
}

bool FootprintTracker::is_stored_dir(const std::string& path) const {
    if (path == "/") return true;
    std::string prefix = path + "/";
    for (const auto& [k, v] : stored_footprint) {
        if (k.rfind(prefix, 0) == 0) return true;
    }
    auto it = virtual_files.find(path);
    if (it != virtual_files.end() && it->second == "<dir>") return true;
    return false;
}

bool FootprintTracker::is_active_dir(const std::string& path) const {
    if (path == "/") return true;
    auto it = virtual_files.find(path);
    if (it != virtual_files.end() && it->second == "<dir>") return true;
    std::string prefix = path + "/";
    for (const auto& [k, v] : active_footprint) {
        if (k.rfind(prefix, 0) == 0) return true;
    }
    return false;
}

bool FootprintTracker::isPathChanged(const std::string& path) const {
    if (!footprint_has_diff) return false;
    for (const auto& p : footprint_added) {
        if (p == path) return true;
    }
    for (const auto& p : footprint_modified) {
        if (p == path) return true;
    }
    for (const auto& p : footprint_removed) {
        if (p == path) return true;
    }
    return false;
}
```
